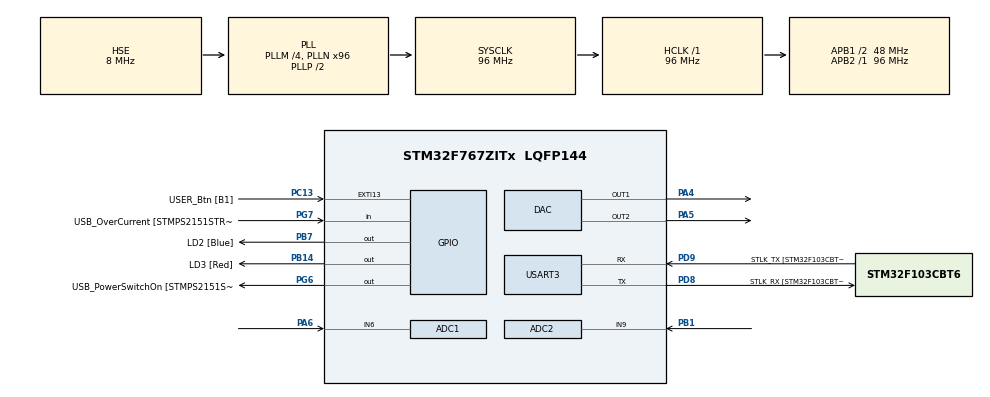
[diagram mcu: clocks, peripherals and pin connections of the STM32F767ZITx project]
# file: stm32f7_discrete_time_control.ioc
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ADC1.Channel-0\#ChannelRegularConversion=ADC_CHANNEL_6
ADC1.NbrOfConversionFlag=1
ADC1.Rank-0\#ChannelRegularConversion=1
ADC1.SamplingTime-0\#ChannelRegularConversion=ADC_SAMPLETIME_3CYCLES
ADC1.master=1
ADC2.Channel-0\#ChannelRegularConversion=ADC_CHANNEL_9
ADC2.NbrOfConversionFlag=1
ADC2.Rank-0\#ChannelRegularConversion=1
ADC2.SamplingTime-0\#ChannelRegularConversion=ADC_SAMPLETIME_3CYCLES
FREERTOS.Tasks01=defaultTask,24,128,StartDefaultTask,Default,NULL
Mcu.Family=STM32F7
Mcu.Name=STM32F767ZITx
Mcu.Package=LQFP144
NVIC.PriorityGroup=NVIC_PRIORITYGROUP_4
NVIC.TIM1_UP_TIM10_IRQn=true\:0\:0\:false\:false\:true\:false\:false\:true
NVIC.TimeBase=TIM1_UP_TIM10_IRQn
NVIC.TimeBaseIP=TIM1
PA1.GPIO_Label=RMII_REF_CLK [LAN8742A-CZ-TR_REFCLK0]
PA1.Signal=ETH_REF_CLK
PA10.GPIO_Label=USB_ID
PA10.Signal=USB_OTG_FS_ID
PA11.GPIO_Label=USB_DM
PA11.Signal=USB_OTG_FS_DM
PA12.GPIO_Label=USB_DP
PA12.Signal=USB_OTG_FS_DP
PA13.GPIO_Label=TMS
PA13.Mode=Serial_Wire
PA13.Signal=SYS_JTMS-SWDIO
PA14.GPIO_Label=TCK
PA14.Mode=Serial_Wire
PA14.Signal=SYS_JTCK-SWCLK
PA2.GPIO_Label=RMII_MDIO [LAN8742A-CZ-TR_MDIO]
PA2.Signal=ETH_MDIO
PA4.Signal=COMP_DAC1_group
PA5.Signal=COMP_DAC2_group
PA6.Signal=ADCx_IN6
PA7.GPIO_Label=RMII_CRS_DV [LAN8742A-CZ-TR_CRS_DV]
PA7.Signal=ETH_CRS_DV
PA8.GPIO_Label=USB_SOF [TP1]
PA8.Signal=USB_OTG_FS_SOF
PA9.GPIO_Label=USB_VBUS
PA9.Signal=USB_OTG_FS_VBUS
PB1.Signal=ADCx_IN9
PB13.GPIO_Label=RMII_TXD1 [LAN8742A-CZ-TR_TXD1]
PB13.Signal=ETH_TXD1
PB14.GPIO_Label=LD3 [Red]
PB14.Signal=GPIO_Output
PB3.GPIO_Label=SWO
PB3.Signal=SYS_JTDO-SWO
PB7.GPIO_Label=LD2 [Blue]
PB7.Signal=GPIO_Output
PC1.GPIO_Label=RMII_MDC [LAN8742A-CZ-TR_MDC]
PC1.Signal=ETH_MDC
PC13.GPIO_Label=USER_Btn [B1]
PC13.Signal=GPXTI13
PC14/OSC32_IN.Mode=LSE-External-Oscillator
PC14/OSC32_IN.Signal=RCC_OSC32_IN
PC15/OSC32_OUT.Mode=LSE-External-Oscillator
PC15/OSC32_OUT.Signal=RCC_OSC32_OUT
PC4.GPIO_Label=RMII_RXD0 [LAN8742A-CZ-TR_RXD0]
PC4.Signal=ETH_RXD0
PC5.GPIO_Label=RMII_RXD1 [LAN8742A-CZ-TR_RXD1]
PC5.Signal=ETH_RXD1
PD8.GPIO_Label=STLK_RX [STM32F103CBT6_PA3]
PD8.Mode=Asynchronous
PD8.Signal=USART3_TX
PD9.GPIO_Label=STLK_TX [STM32F103CBT6_PA2]
PD9.Mode=Asynchronous
PD9.Signal=USART3_RX
PG11.GPIO_Label=RMII_TX_EN [LAN8742A-CZ-TR_TXEN]
PG11.Signal=ETH_TX_EN
PG13.GPIO_Label=RMII_TXD0 [LAN8742A-CZ-TR_TXD0]
PG13.Signal=ETH_TXD0
PG6.GPIO_Label=USB_PowerSwitchOn [STMPS2151STR_EN]
PG6.Signal=GPIO_Output
PG7.GPIO_Label=USB_OverCurrent [STMPS2151STR_FAULT]
PG7.Signal=GPIO_Input
PH0/OSC_IN.GPIO_Label=MCO [STM32F103CBT6_PA8]
PH0/OSC_IN.Mode=HSE-External-Clock-Source
PH0/OSC_IN.Signal=RCC_OSC_IN
PH1/OSC_OUT.Mode=HSE-External-Clock-Source
PH1/OSC_OUT.Signal=RCC_OSC_OUT
ProjectManager.HeapSize=0x200
ProjectManager.StackSize=0x400
ProjectManager.TargetToolchain=STM32CubeIDE
RCC.48MHZClocksFreq_Value=24000000
RCC.AHBFreq_Value=96000000
RCC.APB1CLKDivider=RCC_HCLK_DIV2
RCC.APB1Freq_Value=48000000
RCC.APB1TimFreq_Value=96000000
RCC.APB2Freq_Value=96000000
RCC.APB2TimFreq_Value=96000000
RCC.CortexFreq_Value=96000000
RCC.HCLKFreq_Value=96000000
RCC.HSE_VALUE=8000000
RCC.HSI_VALUE=16000000
RCC.PLLM=4
RCC.PLLMUL=RCC_PLL_MUL9
RCC.PLLN=96
RCC.PLLQ=4
RCC.PLLSourceVirtual=RCC_PLLSOURCE_HSE
RCC.PRESCALERUSB=RCC_USBCLKSOURCE_PLL_DIV1_5
RCC.SYSCLKFreq_VALUE=96000000
RCC.SYSCLKSource=RCC_SYSCLKSOURCE_PLLCLK
RCC.SYSCLKSourceVirtual=RCC_SYSCLKSOURCE_PLLCLK
RCC.USBFreq_Value=48000000
RCC.VCOOutputFreq_Value=192000000
SH.ADCx_IN6.0=ADC1_IN6,IN6
SH.ADCx_IN9.0=ADC2_IN9,IN9
SH.COMP_DAC1_group.0=DAC_OUT1,DAC_OUT1
SH.COMP_DAC2_group.0=DAC_OUT2,DAC_OUT2
USART3.VirtualMode-Asynchronous=VM_ASYNC
VP_FREERTOS_VS_CMSIS_V2.Mode=CMSIS_V2
VP_SYS_VS_tim1.Mode=TIM1
board=NUCLEO-F767ZI

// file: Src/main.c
/* USER CODE BEGIN Header */
/**
  ******************************************************************************
  * @file           : main.c
  * @brief          : Main program body
  ******************************************************************************
  * @attention
  *
  * <h2><center>&copy; Copyright (c) 2019 STMicroelectronics.
  * All rights reserved.</center></h2>
  *
  * This software component is licensed by ST under BSD 3-Clause license,
  * the "License"; You may not use this file except in compliance with the
  * License. You may obtain a copy of the License at:
  *                        opensource.org/licenses/BSD-3-Clause
  *
  ******************************************************************************
  */
/* USER CODE END Header */

#include <application.h>
#include "main.h"
#include "cmsis_os.h"

ADC_HandleTypeDef hadc1;
ADC_HandleTypeDef hadc2;

DAC_HandleTypeDef hdac;

UART_HandleTypeDef huart3;

osThreadId_t defaultTaskHandle;

void SystemClock_Config(void);
static void MX_GPIO_Init(void);
static void MX_USART3_UART_Init(void);
static void MX_ADC1_Init(void);
static void MX_ADC2_Init(void);
static void MX_DAC_Init(void);
void StartDefaultTask(void *argument);

int main(void)
{

  /* MCU Configuration--------------------------------------------------------*/

  /* Reset of all peripherals, Initializes the Flash interface and the Systick. */
  HAL_Init();

  /* Configure the system clock */
  SystemClock_Config();

  /* Initialize all configured peripherals */
  MX_GPIO_Init();
  MX_USART3_UART_Init();
  MX_ADC1_Init();
  MX_ADC2_Init();
  MX_DAC_Init();

  osKernelInitialize();

  /* Create the thread(s) */
  /* definition and creation of defaultTask */
  const osThreadAttr_t defaultTask_attributes = {
    .name = "defaultTask",
    .priority = (osPriority_t) osPriorityNormal,
    .stack_size = 128
  };
  defaultTaskHandle = osThreadNew(StartDefaultTask, NULL, &defaultTask_attributes);

  /* USER CODE BEGIN RTOS_THREADS */
  /* add threads, ... */
  APP_init();
  /* USER CODE END RTOS_THREADS */

  /* Start scheduler */
  osKernelStart();

  /* We should never get here as control is now taken by the scheduler */

  /* Infinite loop */
  while (1)
  {

  }
}

void SystemClock_Config(void)
{
  RCC_OscInitTypeDef RCC_OscInitStruct = {0};
  RCC_ClkInitTypeDef RCC_ClkInitStruct = {0};
  RCC_PeriphCLKInitTypeDef PeriphClkInitStruct = {0};

  /** Configure LSE Drive Capability
  */
  HAL_PWR_EnableBkUpAccess();
  /** Configure the main internal regulator output voltage
  */
  __HAL_RCC_PWR_CLK_ENABLE();
  __HAL_PWR_VOLTAGESCALING_CONFIG(PWR_REGULATOR_VOLTAGE_SCALE3);
  /** Initializes the CPU, AHB and APB busses clocks
  */
  RCC_OscInitStruct.OscillatorType = RCC_OSCILLATORTYPE_HSE;
  RCC_OscInitStruct.HSEState = RCC_HSE_BYPASS;
  RCC_OscInitStruct.PLL.PLLState = RCC_PLL_ON;
  RCC_OscInitStruct.PLL.PLLSource = RCC_PLLSOURCE_HSE;
  RCC_OscInitStruct.PLL.PLLM = 4;
  RCC_OscInitStruct.PLL.PLLN = 96;
  RCC_OscInitStruct.PLL.PLLP = RCC_PLLP_DIV2;
  RCC_OscInitStruct.PLL.PLLQ = 4;
  if (HAL_RCC_OscConfig(&RCC_OscInitStruct) != HAL_OK)
  {
    Error_Handler();
  }
  /** Activate the Over-Drive mode
  */
  if (HAL_PWREx_EnableOverDrive() != HAL_OK)
  {
    Error_Handler();
  }
  /** Initializes the CPU, AHB and APB busses clocks
  */
  RCC_ClkInitStruct.ClockType = RCC_CLOCKTYPE_HCLK|RCC_CLOCKTYPE_SYSCLK
                              |RCC_CLOCKTYPE_PCLK1|RCC_CLOCKTYPE_PCLK2;
  RCC_ClkInitStruct.SYSCLKSource = RCC_SYSCLKSOURCE_PLLCLK;
  RCC_ClkInitStruct.AHBCLKDivider = RCC_SYSCLK_DIV1;
  RCC_ClkInitStruct.APB1CLKDivider = RCC_HCLK_DIV2;
  RCC_ClkInitStruct.APB2CLKDivider = RCC_HCLK_DIV1;

  if (HAL_RCC_ClockConfig(&RCC_ClkInitStruct, FLASH_LATENCY_3) != HAL_OK)
  {
    Error_Handler();
  }
  PeriphClkInitStruct.PeriphClockSelection = RCC_PERIPHCLK_USART3;
  PeriphClkInitStruct.Usart3ClockSelection = RCC_USART3CLKSOURCE_PCLK1;
  if (HAL_RCCEx_PeriphCLKConfig(&PeriphClkInitStruct) != HAL_OK)
  {
    Error_Handler();
  }
}

static void MX_ADC1_Init(void)
{

  ADC_ChannelConfTypeDef sConfig = {0};

  /** Configure the global features of the ADC (Clock, Resolution, Data Alignment and number of conversion)
  */
  hadc1.Instance = ADC1;
  hadc1.Init.ClockPrescaler = ADC_CLOCK_SYNC_PCLK_DIV4;
  hadc1.Init.Resolution = ADC_RESOLUTION_12B;
  hadc1.Init.ScanConvMode = ADC_SCAN_DISABLE;
  hadc1.Init.ContinuousConvMode = DISABLE;
  hadc1.Init.DiscontinuousConvMode = DISABLE;
  hadc1.Init.ExternalTrigConvEdge = ADC_EXTERNALTRIGCONVEDGE_NONE;
  hadc1.Init.ExternalTrigConv = ADC_SOFTWARE_START;
  hadc1.Init.DataAlign = ADC_DATAALIGN_RIGHT;
  hadc1.Init.NbrOfConversion = 1;
  hadc1.Init.DMAContinuousRequests = DISABLE;
  hadc1.Init.EOCSelection = ADC_EOC_SINGLE_CONV;
  if (HAL_ADC_Init(&hadc1) != HAL_OK)
  {
    Error_Handler();
  }
  /** Configure for the selected ADC regular channel its corresponding rank in the sequencer and its sample time.
  */
  sConfig.Channel = ADC_CHANNEL_6;
  sConfig.Rank = ADC_REGULAR_RANK_1;
  sConfig.SamplingTime = ADC_SAMPLETIME_3CYCLES;
  if (HAL_ADC_ConfigChannel(&hadc1, &sConfig) != HAL_OK)
  {
    Error_Handler();
  }

}

static void MX_ADC2_Init(void)
{

  ADC_ChannelConfTypeDef sConfig = {0};

  /** Configure the global features of the ADC (Clock, Resolution, Data Alignment and number of conversion)
  */
  hadc2.Instance = ADC2;
  hadc2.Init.ClockPrescaler = ADC_CLOCK_SYNC_PCLK_DIV4;
  hadc2.Init.Resolution = ADC_RESOLUTION_12B;
  hadc2.Init.ScanConvMode = ADC_SCAN_DISABLE;
  hadc2.Init.ContinuousConvMode = DISABLE;
  hadc2.Init.DiscontinuousConvMode = DISABLE;
  hadc2.Init.ExternalTrigConvEdge = ADC_EXTERNALTRIGCONVEDGE_NONE;
  hadc2.Init.ExternalTrigConv = ADC_SOFTWARE_START;
  hadc2.Init.DataAlign = ADC_DATAALIGN_RIGHT;
  hadc2.Init.NbrOfConversion = 1;
  hadc2.Init.DMAContinuousRequests = DISABLE;
  hadc2.Init.EOCSelection = ADC_EOC_SINGLE_CONV;
  if (HAL_ADC_Init(&hadc2) != HAL_OK)
  {
    Error_Handler();
  }
  /** Configure for the selected ADC regular channel its corresponding rank in the sequencer and its sample time.
  */
  sConfig.Channel = ADC_CHANNEL_9;
  sConfig.Rank = ADC_REGULAR_RANK_1;
  sConfig.SamplingTime = ADC_SAMPLETIME_3CYCLES;
  if (HAL_ADC_ConfigChannel(&hadc2, &sConfig) != HAL_OK)
  {
    Error_Handler();
  }

}

static void MX_DAC_Init(void)
{

  DAC_ChannelConfTypeDef sConfig = {0};

  /** DAC Initialization
  */
  hdac.Instance = DAC;
  if (HAL_DAC_Init(&hdac) != HAL_OK)
  {
    Error_Handler();
  }
  /** DAC channel OUT1 config
  */
  sConfig.DAC_Trigger = DAC_TRIGGER_NONE;
  sConfig.DAC_OutputBuffer = DAC_OUTPUTBUFFER_ENABLE;
  if (HAL_DAC_ConfigChannel(&hdac, &sConfig, DAC_CHANNEL_1) != HAL_OK)
  {
    Error_Handler();
  }
  /** DAC channel OUT2 config
  */
  if (HAL_DAC_ConfigChannel(&hdac, &sConfig, DAC_CHANNEL_2) != HAL_OK)
  {
    Error_Handler();
  }

}

static void MX_USART3_UART_Init(void)
{

  huart3.Instance = USART3;
  huart3.Init.BaudRate = 115200;
  huart3.Init.WordLength = UART_WORDLENGTH_8B;
  huart3.Init.StopBits = UART_STOPBITS_1;
  huart3.Init.Parity = UART_PARITY_NONE;
  huart3.Init.Mode = UART_MODE_TX_RX;
  huart3.Init.HwFlowCtl = UART_HWCONTROL_NONE;
  huart3.Init.OverSampling = UART_OVERSAMPLING_16;
  huart3.Init.OneBitSampling = UART_ONE_BIT_SAMPLE_DISABLE;
  huart3.AdvancedInit.AdvFeatureInit = UART_ADVFEATURE_NO_INIT;
  if (HAL_UART_Init(&huart3) != HAL_OK)
  {
    Error_Handler();
  }

}

static void MX_GPIO_Init(void)
{
  GPIO_InitTypeDef GPIO_InitStruct = {0};

  /* GPIO Ports Clock Enable */
  __HAL_RCC_GPIOC_CLK_ENABLE();
  __HAL_RCC_GPIOH_CLK_ENABLE();
  __HAL_RCC_GPIOA_CLK_ENABLE();
  __HAL_RCC_GPIOB_CLK_ENABLE();
  __HAL_RCC_GPIOD_CLK_ENABLE();
  __HAL_RCC_GPIOG_CLK_ENABLE();

  /*Configure GPIO pin Output Level */
  HAL_GPIO_WritePin(GPIOB, LD3_Pin|LD2_Pin, GPIO_PIN_RESET);

  /*Configure GPIO pin Output Level */
  HAL_GPIO_WritePin(USB_PowerSwitchOn_GPIO_Port, USB_PowerSwitchOn_Pin, GPIO_PIN_RESET);

  /*Configure GPIO pin : USER_Btn_Pin */
  GPIO_InitStruct.Pin = USER_Btn_Pin;
  GPIO_InitStruct.Mode = GPIO_MODE_IT_RISING;
  GPIO_InitStruct.Pull = GPIO_NOPULL;
  HAL_GPIO_Init(USER_Btn_GPIO_Port, &GPIO_InitStruct);

  /*Configure GPIO pins : RMII_MDC_Pin RMII_RXD0_Pin RMII_RXD1_Pin */
  GPIO_InitStruct.Pin = RMII_MDC_Pin|RMII_RXD0_Pin|RMII_RXD1_Pin;
  GPIO_InitStruct.Mode = GPIO_MODE_AF_PP;
  GPIO_InitStruct.Pull = GPIO_NOPULL;
  GPIO_InitStruct.Speed = GPIO_SPEED_FREQ_VERY_HIGH;
  GPIO_InitStruct.Alternate = GPIO_AF11_ETH;
  HAL_GPIO_Init(GPIOC, &GPIO_InitStruct);

  /*Configure GPIO pins : RMII_REF_CLK_Pin RMII_MDIO_Pin RMII_CRS_DV_Pin */
  GPIO_InitStruct.Pin = RMII_REF_CLK_Pin|RMII_MDIO_Pin|RMII_CRS_DV_Pin;
  GPIO_InitStruct.Mode = GPIO_MODE_AF_PP;
  GPIO_InitStruct.Pull = GPIO_NOPULL;
  GPIO_InitStruct.Speed = GPIO_SPEED_FREQ_VERY_HIGH;
  GPIO_InitStruct.Alternate = GPIO_AF11_ETH;
  HAL_GPIO_Init(GPIOA, &GPIO_InitStruct);

  /*Configure GPIO pin : RMII_TXD1_Pin */
  GPIO_InitStruct.Pin = RMII_TXD1_Pin;
  GPIO_InitStruct.Mode = GPIO_MODE_AF_PP;
  GPIO_InitStruct.Pull = GPIO_NOPULL;
  GPIO_InitStruct.Speed = GPIO_SPEED_FREQ_VERY_HIGH;
  GPIO_InitStruct.Alternate = GPIO_AF11_ETH;
  HAL_GPIO_Init(RMII_TXD1_GPIO_Port, &GPIO_InitStruct);

  /*Configure GPIO pins : LD3_Pin LD2_Pin */
  GPIO_InitStruct.Pin = LD3_Pin|LD2_Pin;
  GPIO_InitStruct.Mode = GPIO_MODE_OUTPUT_PP;
  GPIO_InitStruct.Pull = GPIO_NOPULL;
  GPIO_InitStruct.Speed = GPIO_SPEED_FREQ_LOW;
  HAL_GPIO_Init(GPIOB, &GPIO_InitStruct);

  /*Configure GPIO pin : USB_PowerSwitchOn_Pin */
  GPIO_InitStruct.Pin = USB_PowerSwitchOn_Pin;
  GPIO_InitStruct.Mode = GPIO_MODE_OUTPUT_PP;
  GPIO_InitStruct.Pull = GPIO_NOPULL;
  GPIO_InitStruct.Speed = GPIO_SPEED_FREQ_LOW;
  HAL_GPIO_Init(USB_PowerSwitchOn_GPIO_Port, &GPIO_InitStruct);

  /*Configure GPIO pin : USB_OverCurrent_Pin */
  GPIO_InitStruct.Pin = USB_OverCurrent_Pin;
  GPIO_InitStruct.Mode = GPIO_MODE_INPUT;
  GPIO_InitStruct.Pull = GPIO_NOPULL;
  HAL_GPIO_Init(USB_OverCurrent_GPIO_Port, &GPIO_InitStruct);

  /*Configure GPIO pins : USB_SOF_Pin USB_ID_Pin USB_DM_Pin USB_DP_Pin */
  GPIO_InitStruct.Pin = USB_SOF_Pin|USB_ID_Pin|USB_DM_Pin|USB_DP_Pin;
  GPIO_InitStruct.Mode = GPIO_MODE_AF_PP;
  GPIO_InitStruct.Pull = GPIO_NOPULL;
  GPIO_InitStruct.Speed = GPIO_SPEED_FREQ_VERY_HIGH;
  GPIO_InitStruct.Alternate = GPIO_AF10_OTG_FS;
  HAL_GPIO_Init(GPIOA, &GPIO_InitStruct);

  /*Configure GPIO pin : USB_VBUS_Pin */
  GPIO_InitStruct.Pin = USB_VBUS_Pin;
  GPIO_InitStruct.Mode = GPIO_MODE_INPUT;
  GPIO_InitStruct.Pull = GPIO_NOPULL;
  HAL_GPIO_Init(USB_VBUS_GPIO_Port, &GPIO_InitStruct);

  /*Configure GPIO pins : RMII_TX_EN_Pin RMII_TXD0_Pin */
  GPIO_InitStruct.Pin = RMII_TX_EN_Pin|RMII_TXD0_Pin;
  GPIO_InitStruct.Mode = GPIO_MODE_AF_PP;
  GPIO_InitStruct.Pull = GPIO_NOPULL;
  GPIO_InitStruct.Speed = GPIO_SPEED_FREQ_VERY_HIGH;
  GPIO_InitStruct.Alternate = GPIO_AF11_ETH;
  HAL_GPIO_Init(GPIOG, &GPIO_InitStruct);

}

void StartDefaultTask(void *argument)
{

  /* USER CODE BEGIN 5 */
  /* Infinite loop */
  for(;;)
  {
	  osDelay(1000);
  }
  /* USER CODE END 5 */
}

void HAL_TIM_PeriodElapsedCallback(TIM_HandleTypeDef *htim)
{
  if (htim->Instance == TIM1) {
    HAL_IncTick();
  }
}

void Error_Handler(void)
{
}

/************************ (C) COPYRIGHT STMicroelectronics *****END OF FILE****/
